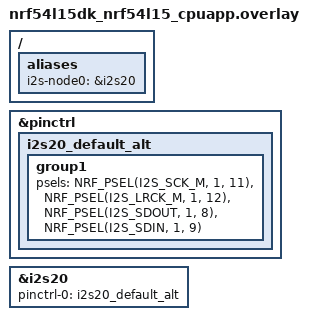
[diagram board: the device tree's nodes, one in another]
/*
 * Copyright (c) 2025 Nordic Semiconductor ASA
 *
 * SPDX-License-Identifier: LicenseRef-Nordic-5-Clause
 */

/* Test requires GPIO loopback:
 * P1.08 - P1.09
 */

/ {
	aliases {
		i2s-node0 = &i2s20;
	};
};

&pinctrl {
	i2s20_default_alt: i2s20_default_alt {
		group1 {
			psels = <NRF_PSEL(I2S_SCK_M, 1, 11)>,
				<NRF_PSEL(I2S_LRCK_M, 1, 12)>,
				<NRF_PSEL(I2S_SDOUT, 1, 8)>,
				<NRF_PSEL(I2S_SDIN, 1, 9)>;
		};
	};
};

&i2s20 {
	status = "okay";
	pinctrl-0 = <&i2s20_default_alt>;
	pinctrl-names = "default";
};
